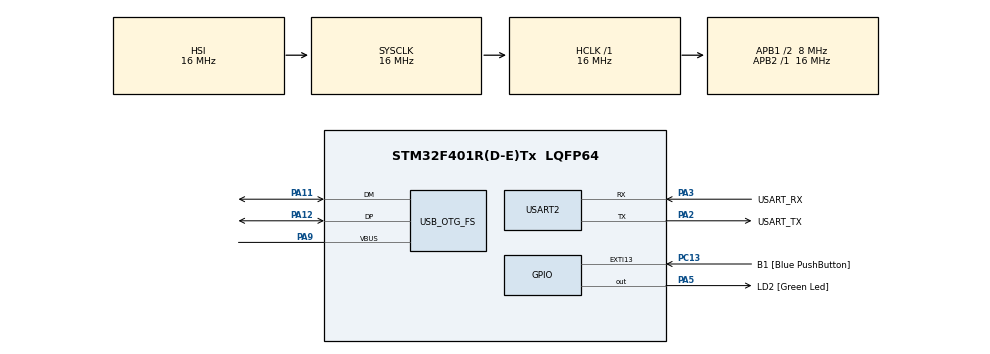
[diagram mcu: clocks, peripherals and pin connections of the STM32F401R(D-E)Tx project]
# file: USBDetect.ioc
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Mcu.Family=STM32F4
Mcu.Name=STM32F401R(D-E)Tx
Mcu.Package=LQFP64
NVIC.OTG_FS_IRQn=true\:0\:0\:false\:false\:true\:false\:true\:true
NVIC.PriorityGroup=NVIC_PRIORITYGROUP_4
PA11.Mode=Host_Only
PA11.Signal=USB_OTG_FS_DM
PA12.Mode=Host_Only
PA12.Signal=USB_OTG_FS_DP
PA13.GPIO_Label=TMS
PA13.Mode=Trace_Asynchronous_SW
PA13.Signal=SYS_JTMS-SWDIO
PA14.GPIO_Label=TCK
PA14.Mode=Trace_Asynchronous_SW
PA14.Signal=SYS_JTCK-SWCLK
PA2.GPIO_Label=USART_TX
PA2.GPIO_Mode=GPIO_MODE_AF_PP
PA2.GPIO_PuPd=GPIO_NOPULL
PA2.GPIO_Speed=GPIO_SPEED_FREQ_LOW
PA2.Mode=Asynchronous
PA2.Signal=USART2_TX
PA3.GPIO_Label=USART_RX
PA3.GPIO_Mode=GPIO_MODE_AF_PP
PA3.GPIO_PuPd=GPIO_NOPULL
PA3.GPIO_Speed=GPIO_SPEED_FREQ_LOW
PA3.Mode=Asynchronous
PA3.Signal=USART2_RX
PA5.GPIO_Label=LD2 [Green Led]
PA5.GPIO_Mode=GPIO_MODE_OUTPUT_PP
PA5.GPIO_PuPd=GPIO_NOPULL
PA5.GPIO_Speed=GPIO_SPEED_FREQ_LOW
PA5.Signal=GPIO_Output
PA9.Mode=Activate_VBUS
PA9.Signal=USB_OTG_FS_VBUS
PB3.GPIO_Label=SWO
PB3.Mode=Trace_Asynchronous_SW
PB3.Signal=SYS_JTDO-SWO
PC13-ANTI_TAMP.GPIO_Label=B1 [Blue PushButton]
PC13-ANTI_TAMP.GPIO_ModeDefaultEXTI=GPIO_MODE_IT_FALLING
PC13-ANTI_TAMP.GPIO_PuPd=GPIO_NOPULL
PC13-ANTI_TAMP.Signal=GPXTI13
PC14-OSC32_IN.Mode=LSE-External-Oscillator
PC14-OSC32_IN.Signal=RCC_OSC32_IN
PC15-OSC32_OUT.Mode=LSE-External-Oscillator
PC15-OSC32_OUT.Signal=RCC_OSC32_OUT
PH0\ -\ OSC_IN.Mode=HSE-External-Clock-Source
PH0\ -\ OSC_IN.Signal=RCC_OSC_IN
PH1\ -\ OSC_OUT.Mode=HSE-External-Clock-Source
PH1\ -\ OSC_OUT.Signal=RCC_OSC_OUT
ProjectManager.HeapSize=0x200
ProjectManager.StackSize=0x400
ProjectManager.TargetToolchain=STM32CubeIDE
RCC.48MHZClocksFreq_Value=48000000
RCC.AHBFreq_Value=16000000
RCC.APB1CLKDivider=RCC_HCLK_DIV2
RCC.APB1Freq_Value=8000000
RCC.APB1TimFreq_Value=16000000
RCC.APB2Freq_Value=16000000
RCC.APB2TimFreq_Value=16000000
RCC.CortexFreq_Value=16000000
RCC.HCLKFreq_Value=16000000
RCC.HSE_VALUE=8000000
RCC.HSI_VALUE=16000000
RCC.PLLM=4
RCC.PLLN=72
RCC.PLLP=RCC_PLLP_DIV4
RCC.PLLQ=3
RCC.SYSCLKFreq_VALUE=16000000
RCC.VCOOutputFreq_Value=144000000
USART2.VirtualMode=VM_ASYNC
USB_HOST.BSP.number=1
USB_HOST.USBH_HandleTypeDef-ALL_Classes_FS=hUsbHostFS
USB_HOST.VirtualModeFS=All_Classes
USB_HOST0.BSP.STBoard=false
USB_HOST0.BSP.api=Unknown
USB_HOST0.BSP.condition=ALL_SW_VBUS_DRIVE_FS \= false
USB_HOST0.BSP.instance=PA5
USB_HOST0.BSP.ip=GPIO
USB_HOST0.BSP.mode=Output
USB_HOST0.BSP.name=Drive_VBUS_FS
USB_HOST0.BSP.solution=PA5
USB_OTG_FS.VirtualMode=Host_Only
USB_OTG_FS.phy_itface=HCD_PHY_EMBEDDED
VP_USB_HOST_VS_USB_HOST_ALL_CLASS_FS.Mode=ALL_Classes_FS
board=NUCLEO-F401RE

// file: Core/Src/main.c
/* USER CODE BEGIN Header */
/**
  ******************************************************************************
  * @file           : main.c
  * @brief          : Main program body
  ******************************************************************************
  * @attention
  *
  * Copyright (c) 2025 STMicroelectronics.
  * All rights reserved.
  *
  * This software is licensed under terms that can be found in the LICENSE file
  * in the root directory of this software component.
  * If no LICENSE file comes with this software, it is provided AS-IS.
  *
  ******************************************************************************
  */
/* USER CODE END Header */
#include "main.h"
#include "usart.h"
#include "usb_host.h"
#include "gpio.h"
#include <string.h>  /* Include for strcmp */

/* USER CODE BEGIN PD */
#define MAX_BOARD_NAME_LENGTH 50
char detected_board_name[MAX_BOARD_NAME_LENGTH] = "No Device";  // Store the detected board name
char selected_board_name[MAX_BOARD_NAME_LENGTH] = "Arduino UNO R3";  // You can set this to the selected board's name

/* USER CODE END PD */

void SystemClock_Config(void);
void MX_USB_HOST_Process(void);

int main(void)
{

  /* MCU Configuration--------------------------------------------------------*/

  /* Reset of all peripherals, Initializes the Flash interface and the Systick. */
  HAL_Init();

  /* Configure the system clock */
  SystemClock_Config();

  /* Initialize all configured peripherals */
  MX_GPIO_Init();
  MX_USART2_UART_Init();
  MX_USB_HOST_Init();

  /* Infinite loop */
  /* USER CODE BEGIN WHILE */
  while (1)
  {
      const char* detected_device = check_usb_device();  // Get the name of the detected device
      strncpy(detected_board_name, detected_device, MAX_BOARD_NAME_LENGTH - 1);
      detected_board_name[MAX_BOARD_NAME_LENGTH - 1] = '\0'; // Ensure null termination

      if (strcmp(detected_board_name, "No Device") == 0) {
          // If no device is detected, do nothing or handle accordingly
          printf("No USB device detected.\r\n");
      } else {
          // If a device is detected, check if it matches the selected board
          if (strcmp(detected_board_name, selected_board_name) == 0) {
              printf("Detected board matches the selected board: %s\r\n", detected_board_name);
              if (strcmp(detected_board_name, "Arduino UNO R3") == 0) {  // Corrected comparison
                      printf("Triggering bootloader\r\n");
                      trigger_arduino_bootloader();
                  }
          } else {
              printf("Board mismatch! Detected: %s, Selected: %s\r\n", detected_board_name, selected_board_name);
          }
      }

      MX_USB_HOST_Process();  // Process USB Host tasks
      HAL_Delay(250);  // Small delay to avoid too fast polling
  }

  /* USER CODE END 3 */
}

void SystemClock_Config(void)
{
  RCC_OscInitTypeDef RCC_OscInitStruct = {0};
  RCC_ClkInitTypeDef RCC_ClkInitStruct = {0};

  /** Configure the main internal regulator output voltage
  */
  __HAL_RCC_PWR_CLK_ENABLE();
  __HAL_PWR_VOLTAGESCALING_CONFIG(PWR_REGULATOR_VOLTAGE_SCALE2);

  /** Initializes the RCC Oscillators according to the specified parameters
  * in the RCC_OscInitTypeDef structure.
  */
  RCC_OscInitStruct.OscillatorType = RCC_OSCILLATORTYPE_HSI|RCC_OSCILLATORTYPE_HSE;
  RCC_OscInitStruct.HSEState = RCC_HSE_BYPASS;
  RCC_OscInitStruct.HSIState = RCC_HSI_ON;
  RCC_OscInitStruct.HSICalibrationValue = RCC_HSICALIBRATION_DEFAULT;
  RCC_OscInitStruct.PLL.PLLState = RCC_PLL_ON;
  RCC_OscInitStruct.PLL.PLLSource = RCC_PLLSOURCE_HSE;
  RCC_OscInitStruct.PLL.PLLM = 4;
  RCC_OscInitStruct.PLL.PLLN = 72;
  RCC_OscInitStruct.PLL.PLLP = RCC_PLLP_DIV4;
  RCC_OscInitStruct.PLL.PLLQ = 3;
  if (HAL_RCC_OscConfig(&RCC_OscInitStruct) != HAL_OK)
  {
    Error_Handler();
  }

  /** Initializes the CPU, AHB and APB buses clocks
  */
  RCC_ClkInitStruct.ClockType = RCC_CLOCKTYPE_HCLK|RCC_CLOCKTYPE_SYSCLK
                              |RCC_CLOCKTYPE_PCLK1|RCC_CLOCKTYPE_PCLK2;
  RCC_ClkInitStruct.SYSCLKSource = RCC_SYSCLKSOURCE_HSI;
  RCC_ClkInitStruct.AHBCLKDivider = RCC_SYSCLK_DIV1;
  RCC_ClkInitStruct.APB1CLKDivider = RCC_HCLK_DIV2;
  RCC_ClkInitStruct.APB2CLKDivider = RCC_HCLK_DIV1;

  if (HAL_RCC_ClockConfig(&RCC_ClkInitStruct, FLASH_LATENCY_0) != HAL_OK)
  {
    Error_Handler();
  }
}

void Error_Handler(void)
{
  __disable_irq();
  while (1)
  {
  }
}
